# ATtiny828 register map
Vendor: Atmel; File version: 1.0
CPU: other r0p0, little endian, no MPU, no FPU, 4 interrupt priority bits
Registers are 8-bit, read-write, reset 0x0 unless marked. A register's access mark holds for its fields unless they carry their own. Offsets are from the block's base; [hi:lo] are bit positions; {n}, {i} and the like mark numbered series; 'fields as' and 'values as' point back to an identical list.

## CPU — CPU Registers
Base 0x0000003E
0x00 GPIOR0 — General Purpose I/O Register 0
0x0C GPIOR1 — General Purpose I/O Register 1
0x0D GPIOR2 — General Purpose I/O Register 2
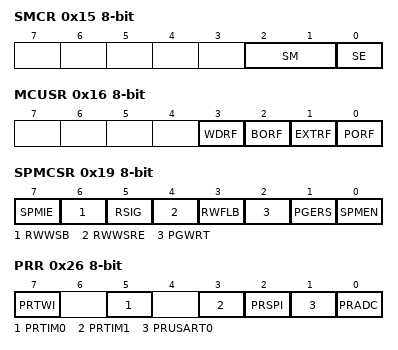
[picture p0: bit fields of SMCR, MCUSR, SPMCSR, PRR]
0x15 SMCR — Sleep Mode Control Register
  [2:1] SM — Sleep Mode Select Bits
    0=IDLE; 1=ADC (ADC Noise Reduction (If Available)); 2=PDOWN (Power Down)
  [0] SE — Sleep Enable
0x16 MCUSR — MCU Status Register
  [3] WDRF — Watchdog Reset Flag
  [2] BORF — Brown-out Reset Flag
  [1] EXTRF — External Reset Flag
  [0] PORF — Power-on reset flag
0x17 MCUCR — MCU Control Register
  [1] IVSEL — Interrupt Vector Select
0x18 CCP — Configuration Change Protection
0x19 SPMCSR — Store Program Memory Control and Status Register
  [7] SPMIE — SPM Interrupt Enable
  [6] RWWSB — Read-While-Write Section Busy
  [5] RSIG — Read Device Signature Imprint Table
  [4] RWWSRE — Read-While-Write section read enable
  [3] RWFLB — Read/Write Fuse and Lock Bits
  [2] PGWRT — Page Write
  [1] PGERS — Page Erase
  [0] SPMEN — Store Program Memory Enable
0x23 CLKPR — Clock Prescale Register
  [3:0] CLKPS — Clock Prescaler Select Bits
    0=1; 1=2; 2=4; 3=8; 4=16; 5=32; 6=64; 7=128; 8=256
0x26 PRR — Power Reduction Register
  [7] PRTWI — Power Reduction TWI
  [5] PRTIM0 — Power Reduction Timer/Counter0
  [3] PRTIM1 — Power Reduction Timer/Counter1
  [2] PRSPI — Power Reduction SPI
  [1] PRUSART0 — Power Reduction USART 0
  [0] PRADC — Power Reduction ADC
0x28 OSCCAL0 — Oscillator Calibration Register 8MHz
0x29 OSCCAL1 — Oscillator Calibration Register 32kHz
0xB2 OSCTCAL0A — Oscillator Temperature Calibration Register A
0xB3 OSCTCAL0B — Oscillator Temperature Calibration Register B

## EEPROM
Base 0x0000003F
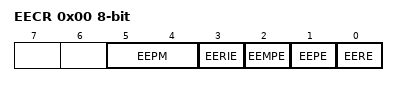
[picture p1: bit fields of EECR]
0x00 EECR — EEPROM Control Register
  [5:4] EEPM — EEPROM Programming Mode Bits
    0=ERASE_AND_WRITE_IN_ONE_OPERATION; 1=ERASE_ONLY; 2=WRITE_ONLY
  [3] EERIE — EEProm Ready Interrupt Enable
  [2] EEMPE — EEPROM Master Write Enable
  [1] EEPE — EEPROM Write Enable
  [0] EERE — EEPROM Read Enable
0x01 EEDR — EEPROM Data Register
0x02 EEAR — EEPROM Read/Write Access
0x02 EEARL — EEPROM Read/Write Access

## EXINT — External Interrupts
Base 0x0000003B
0x00 PCIFR — Pin Change Interrupt Flag Register
  [3:0] PCIF — Pin Change Interrupt Flags
0x01 EIFR — External Interrupt Flag Register
  [1:0] INTF — External Interrupt Flags
0x02 EIMSK — External Interrupt Mask Register
  [1:0] INT — External Interrupt Request Enables
0x2D PCICR — Pin Change Interrupt Control Register
  [3:0] PCIE — Pin Change Interrupt Enables
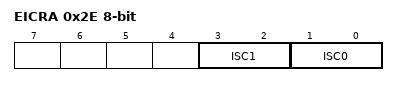
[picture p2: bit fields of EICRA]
0x2E EICRA — External Interrupt Control Register
  [3:2] ISC1 — External Interrupt Sense Control 1 Bits
    0=LOW_LEVEL_OF_INTX; 1=ANY_LOGICAL_CHANGE_OF_INTX; 2=FALLING_EDGE_OF_INTX; 3=RISING_EDGE_OF_INTX
  [1:0] ISC0 — External Interrupt Sense Control 0 Bits
    values as ISC1
{0x30+i} PCMSK{i} (i=0..2) — Pin Change Mask Register {i}
  [7:0] PCINT — Pin Change Enable Masks
0x38 PCMSK3 — Pin Change Mask Register 3
  [3:0] PCINT — Pin Change Enable Masks

## FUSE — Fuses
Base 0x00000000
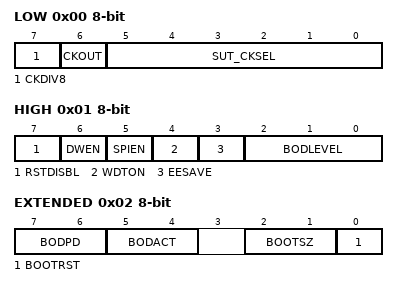
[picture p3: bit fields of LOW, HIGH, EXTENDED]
0x00 LOW
  [7] CKDIV8 — Divide clock by 8 internally
  [6] CKOUT — Clock output on PORTB0
  [5:0] SUT_CKSEL — Select Clock Source
    1=EXTCLK_6CK_14CK_0MS (Ext. Clock; Start-up time PWRDWN/RESET: 6 + 14 CK + 0 ms); 2=INTRCOSC_8MHZ_6CK_14CK_0MS (Int. RC Osc. 8 MHz; Start-up time PWRDWN/RESET: 6 + 14 CK + 0 ms); 3=INTULPOSC_32KHZ_6CK_14CK_0MS (Int. ULP Osc. 32kHz; Start-up time PWRDWN/RESET: 6 + 14 CK + 0 ms); 17=EXTCLK_6CK_14CK_4MS1 (Ext. Clock; Start-up time PWRDWN/RESET: 6 + 14 CK + 4.1 ms); 18=INTRCOSC_8MHZ_6CK_14CK_4MS1 (Int. RC Osc. 8 MHz; Start-up time PWRDWN/RESET: 6 + 14 CK + 4.1 ms); 19=INTULPOSC_32KHZ_6CK_14CK_4MS1 (Int. ULP Osc. 32kHz; Start-up time PWRDWN/RESET: 6 + 14 CK + 4.1 ms); 49=EXTCLK_6CK_14CK_65MS (Ext. Clock; Start-up time PWRDWN/RESET: 6 + 14 CK + 65 ms); 50=INTRCOSC_8MHZ_6CK_14CK_65MS (Int. RC Osc. 8 MHz; Start-up time PWRDWN/RESET: 6 + 14 CK + 65 ms); 51=INTULPOSC_32KHZ_6CK_14CK_65MS (Int. ULP Osc. 32kHz; Start-up time PWRDWN/RESET: 6 + 14 CK + 65 ms)
0x01 HIGH
  [7] RSTDISBL — Reset Disabled (Enable PC6 as i/o pin)]
  [6] DWEN — Debug Wire enable
  [5] SPIEN — Serial program downloading (SPI) enabled
  [4] WDTON — Watch-dog Timer always on
  [3] EESAVE — Preserve EEPROM through the Chip Erase cycle
  [2:0] BODLEVEL — Brown-out Detector trigger level
    4=4V3 (Brown-out detection at VCC=4.3 V); 5=2V7 (Brown-out detection at VCC=2.7 V); 6=1V8 (Brown-out detection at VCC=1.8 V); 7=DISABLED (Brown-out detection disabled)
0x02 EXTENDED
  [7:6] BODPD — BOD mode of operation when the device is in sleep mode
    1=BOD_SAMPLED (Sampled); 2=BOD_ENABLED (Enabled); 3=BOD_DISABLED (Disabled)
  [5:4] BODACT — BOD mode of operation when the device is active or idle
    values as BODPD
  [2:1] BOOTSZ — Select boot size
    0=1024W_0C00 (Boot Flash size=1024 words Boot address=$0C00); 1=512W_0E00 (Boot Flash size=512 words Boot address=$0E00); 2=256W_0F00 (Boot Flash size=256 words Boot address=$0F00); 3=128W_0F80 (Boot Flash size=128 words Boot address=$0F80)
  [0] BOOTRST — Boot Reset vector Enabled
